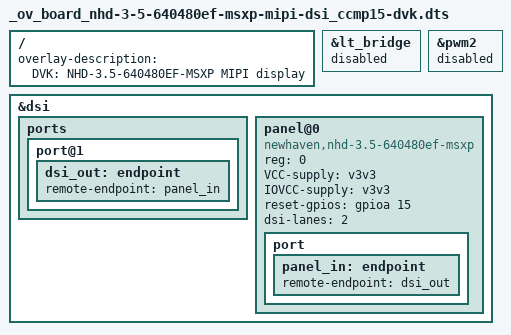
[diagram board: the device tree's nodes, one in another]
/*
 * Copyright 2024 Digi International Inc.
 *
 * Permission to use, copy, modify, and/or distribute this software for any
 * purpose with or without fee is hereby granted, provided that the above
 * copyright notice and this permission notice appear in all copies.
 * THE SOFTWARE IS PROVIDED "AS IS" AND THE AUTHOR DISCLAIMS ALL WARRANTIES
 * WITH REGARD TO THIS SOFTWARE INCLUDING ALL IMPLIED WARRANTIES OF
 * MERCHANTABILITY AND FITNESS. IN NO EVENT SHALL THE AUTHOR BE LIABLE FOR
 * ANY SPECIAL, DIRECT, INDIRECT, OR CONSEQUENTIAL DAMAGES OR ANY DAMAGES
 * WHATSOEVER RESULTING FROM LOSS OF USE, DATA OR PROFITS, WHETHER IN AN
 * ACTION OF CONTRACT, NEGLIGENCE OR OTHER TORTIOUS ACTION, ARISING OUT OF
 * OR IN CONNECTION WITH THE USE OR PERFORMANCE OF THIS SOFTWARE.
 */

#include <dt-bindings/gpio/gpio.h>

/dts-v1/;
/plugin/;

/ {
	fragment@0 {
		target-path = "/";
		__overlay__ {
			overlay-description = "DVK: NHD-3.5-640480EF-MSXP MIPI display";
		};
	};

	/* Disable LT8912 */
	fragment@1 {
		target = <&lt_bridge>;
		__overlay__ {
			status = "disabled";
		};
	};

	/*
	 * Disable PWM backlight
	 * Provide Backlight from an external power source: 19.2V/40mA
	 * Use BCKL_PWM line as the RESET line instead
	 */
	fragment@2 {
		target = <&pwm2>;
		__overlay__ {
			status = "disabled";
		};
	};

	/* Add NHD-3.5-640480EF-MSXP MIPI display panel */
	fragment@3 {
		target = <&dsi>;
		__overlay__ {
			#address-cells = <1>;
			#size-cells = <0>;

			ports {
				port@1 {
					dsi_out: endpoint {
						remote-endpoint = <&panel_in>;
					};
				};
			};

			panel@0 {
				compatible = "newhaven,nhd-3.5-640480ef-msxp";
				reg = <0>;
				VCC-supply = <&v3v3>;
				IOVCC-supply = <&v3v3>;
				reset-gpios = <&gpioa 15 GPIO_ACTIVE_HIGH>; /* BCKL_PWM */
				dsi-lanes = <2>;
				status = "okay";

				port {
					panel_in: endpoint {
						remote-endpoint = <&dsi_out>;
					};
				};
			};
		};
	};
};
